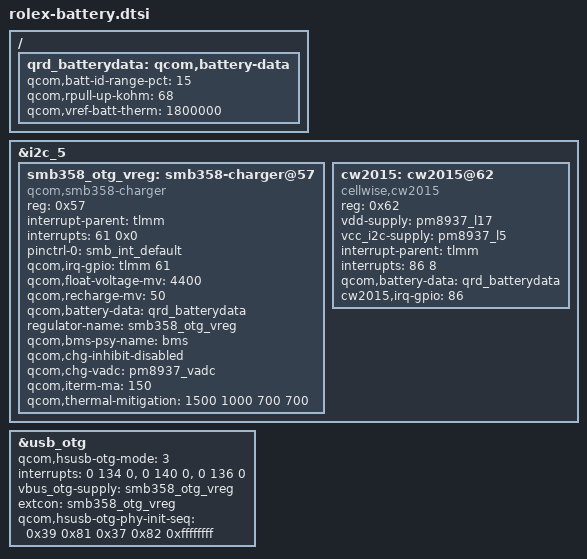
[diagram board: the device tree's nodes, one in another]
/*
 * Copyright (c) 2016, The Linux Foundation. All rights reserved.
 * Copyright (C) 2018 XiaoMi, Inc.
 *
 * This program is free software; you can redistribute it and/or modify
 * it under the terms of the GNU General Public License version 2 and
 * only version 2 as published by the Free Software Foundation.
 *
 * This program is distributed in the hope that it will be useful,
 * but WITHOUT ANY WARRANTY; without even the implied warranty of
 * MERCHANTABILITY or FITNESS FOR A PARTICULAR PURPOSE.  See the
 * GNU General Public License for more details.
 */

&i2c_5 {
	status = "ok";
	smb358_otg_vreg: smb358-charger@57 {
		compatible = "qcom,smb358-charger";
		reg = <0x57>;
		interrupt-parent = <&tlmm>;
		interrupts = <61 0x0>;
		pinctrl-names = "default";
		pinctrl-0 = <&smb_int_default>;
		qcom,irq-gpio = <&tlmm 61 0x0>;
		qcom,float-voltage-mv = <4400>;
		qcom,recharge-mv = <50>;
		qcom,battery-data = <&qrd_batterydata>;
		regulator-name = "smb358_otg_vreg";
		qcom,bms-psy-name = "bms";
		qcom,chg-inhibit-disabled;	
		qcom,chg-vadc = <&pm8937_vadc>;
		qcom,iterm-ma = <150>;
		/* Optional Properties */
		qcom,thermal-mitigation = <1500 1000 700 700>;
		status = "ok";
	};
	cw2015: cw2015@62 {
		compatible = "cellwise,cw2015";
		reg = <0x62>;
		vdd-supply = <&pm8937_l17>;
		vcc_i2c-supply = <&pm8937_l5>;
		interrupt-parent = <&tlmm>;
		interrupts = <86 8>;
		qcom,battery-data = <&qrd_batterydata>;
		cw2015,irq-gpio=<86>;
	};
};

&usb_otg {
	qcom,hsusb-otg-mode = <3>;
	interrupts = <0 134 0>,<0 140 0>,<0 136 0>;
	interrupt-names = "core_irq", "async_irq", "phy_irq";
	vbus_otg-supply = <&smb358_otg_vreg>;
	extcon = <&smb358_otg_vreg>;
	qcom,hsusb-otg-phy-init-seq =
		<0x39 0x81 0x37 0x82 0xffffffff>;
};

/ {
qrd_batterydata: qcom,battery-data {
		qcom,batt-id-range-pct = <15>;
		qcom,rpull-up-kohm = <68>;
		qcom,vref-batt-therm = <1800000>;

		#include "battery/batterydata-wingtech-feimaotui_SONY-4v4-3030mah.dtsi"
		#include "battery/batterydata-wingtech-xingwangda_ATL-4v4-3030mah.dtsi"

	};

};
